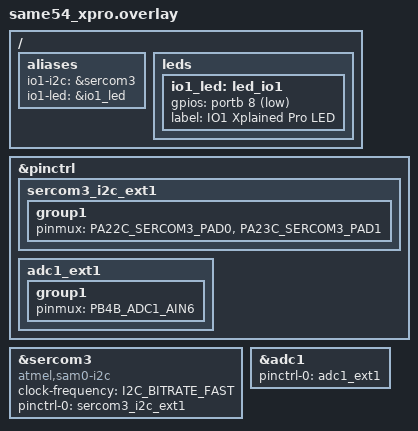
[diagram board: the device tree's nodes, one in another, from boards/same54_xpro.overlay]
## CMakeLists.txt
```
# ml-model-update demo: cloud-updatable ML (IOTM blob) on IO1 Xplained Pro
# sensors. Own src/main.c; uses the quickstart provisioning flow (public CA
# roots only). Regenerate src/model_builtin.h with tools/build_model.py if
# the blob format changes.
cmake_minimum_required(VERSION 3.20.0)
find_package(Zephyr REQUIRED HINTS $ENV{ZEPHYR_BASE})
project(iotc_demo_ml_model_update)

target_sources(app PRIVATE src/main.c)

include(${CMAKE_CURRENT_SOURCE_DIR}/../../common/cmake/iotc_sdk_samples.cmake)

# quickstart_credentials.h: PUBLIC CA roots only (no device key). The
# per-device key/cert is provisioned on-chip (iotcprov provision) into NVS.
target_include_directories(app PRIVATE ${IOTC_SDK_SAMPLES_DIR}/quickstart/src)
```

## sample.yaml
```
sample:
  name: IOTCONNECT ML model update demo
  description: |
    Cloud-updatable tiny-MLP on IO1 Xplained Pro sensors: the model is a
    validated data blob (IOTM) pushed from IOTCONNECT as a C2D command,
    hot-swapped without reflash and persisted to NVS.
common:
  tags: iotconnect ml
  harness: console
tests:
  sample.iotconnect.ml_model_update.build:
    build_only: true
    platform_allow:
      - same54_xpro
```

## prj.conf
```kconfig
# ml-model-update demo - vendor-neutral baseline.
# Board-specific networking/bearer settings live in boards/<board>.conf.

# --- Turn on the SDK (selects the net/TLS/MQTT/SNTP/HTTP stack) -------------
CONFIG_IOTCONNECT=y
CONFIG_IOTCONNECT_DRA=y

# No identity is compiled in: the device is provisioned from the serial
# prompt (quickstart flow) -- iotcprov provision <duid>, register the printed
# cert, paste iotcDeviceConfig.json (iotc config), reboot.
CONFIG_IOTCONNECT_CPID=""
CONFIG_IOTCONNECT_ENV=""
CONFIG_IOTCONNECT_DUID=""
CONFIG_IOTCONNECT_CT_AWS=y
# Region-specific AWS discovery endpoint (from the device config package).
CONFIG_IOTCONNECT_DRA_DISCOVERY_HOST="awsdiscovery.iotconnect.io"

# --- On-device provisioning (identity in NVS + shell commands) --------------
CONFIG_IOTCONNECT_IDENTITY_NVS=y
CONFIG_IOTCONNECT_ONDEVICE_KEYGEN=y
CONFIG_IOTCONNECT_SHELL=y
CONFIG_MBEDTLS_USER_CONFIG_FILE="iotc_mbedtls_config.h"   # enables X509_CREATE_C
CONFIG_PSA_WANT_ALG_ECDSA=y
CONFIG_PSA_WANT_KEY_TYPE_ECC_KEY_PAIR_GENERATE=y
CONFIG_PSA_WANT_KEY_TYPE_ECC_KEY_PAIR_EXPORT=y
CONFIG_PSA_WANT_ECC_SECP_R1_256=y

# --- Shell (base64 cert/key + JSON paste need generous buffers) -------------
CONFIG_SHELL=y
CONFIG_SHELL_CMD_BUFF_SIZE=3072
CONFIG_SHELL_BACKEND_SERIAL_RX_RING_BUFFER_SIZE=4096
CONFIG_SHELL_STACK_SIZE=8192
CONFIG_KERNEL_SHELL=y

# --- Networking (native Zephyr IP stack) -----------------------------------
CONFIG_NETWORKING=y
CONFIG_NET_NATIVE=y
CONFIG_NET_IPV4=y
CONFIG_NET_IPV6=n
CONFIG_NET_TCP=y
CONFIG_NET_UDP=y
CONFIG_NET_SOCKETS=y
CONFIG_NET_SOCKETS_SOCKOPT_TLS=y
CONFIG_NET_SOCKETS_TLS_MAX_CONTEXTS=4
CONFIG_DNS_RESOLVER=y
CONFIG_NET_CONNECTION_MANAGER=y
CONFIG_NET_MGMT=y
CONFIG_NET_MGMT_EVENT=y
CONFIG_POSIX_API=y

# --- TLS / mbedTLS (Zephyr 4.x symbol set) ---------------------------------
CONFIG_TLS_CREDENTIALS=y
CONFIG_MBEDTLS=y
CONFIG_MBEDTLS_ENABLE_HEAP=y
CONFIG_MBEDTLS_HEAP_SIZE=75000
CONFIG_MBEDTLS_SSL_MAX_CONTENT_LEN=16384
CONFIG_MBEDTLS_PEM_PARSE_C=y
CONFIG_MBEDTLS_SSL_SERVER_NAME_INDICATION=y
# Ciphersuites: ECDHE-RSA covers AWS/Azure RSA broker roots; ECDHE-ECDSA covers
# ECC device/broker certs (common with IOTCONNECT). Both AES-128-GCM-SHA256.
CONFIG_MBEDTLS_CIPHERSUITE_TLS_ECDHE_RSA_WITH_AES_128_GCM_SHA256=y
# discovery.iotconnect.io (production instances) only accepts TLS 1.2 CBC suites
CONFIG_MBEDTLS_CIPHERSUITE_TLS_ECDHE_RSA_WITH_AES_128_CBC_SHA256=y
CONFIG_MBEDTLS_CIPHERSUITE_TLS_ECDHE_ECDSA_WITH_AES_128_GCM_SHA256=y
CONFIG_ENTROPY_GENERATOR=y

# --- MQTT / HTTP / SNTP -----------------------------------------------------
CONFIG_MQTT_LIB=y
CONFIG_MQTT_LIB_TLS=y
CONFIG_MQTT_KEEPALIVE=30
CONFIG_HTTP_CLIENT=y
CONFIG_SNTP=y

# --- Time (apply SNTP to realtime clock for cert validity) -----------------
CONFIG_POSIX_TIMERS=y

# --- Settings / NVS (identity + DRA cache persistence) ---------------------
CONFIG_SETTINGS=y
CONFIG_SETTINGS_NVS=y
CONFIG_NVS=y
CONFIG_FLASH=y
CONFIG_FLASH_MAP=y

# --- libc / heap / stacks ---------------------------------------------------
# Board default libc = picolibc. cJSON serializes telemetry doubles via libc
# sprintf("%g"); picolibc needs float printf explicitly enabled or doubles
# render as the literal "*float*".
CONFIG_PICOLIBC_IO_FLOAT=y
CONFIG_MAIN_STACK_SIZE=8192
CONFIG_HEAP_MEM_POOL_SIZE=32768
CONFIG_IOTCONNECT_THREAD_STACK_SIZE=4096

# --- Logging ----------------------------------------------------------------
CONFIG_LOG=y
CONFIG_IOTCONNECT_LOG_LEVEL_INF=y

# ml-model-update: IO1 Xplained Pro sensors + LED, model blob handling.
CONFIG_GPIO=y
CONFIG_I2C=y
CONFIG_ADC=y
# base64 decode of pushed model blobs; CRC32 validation of their weights.
CONFIG_BASE64=y
CONFIG_CRC=y
# C2D "reboot" command.
CONFIG_REBOOT=y

# Device vitals: append a "sys" object (CPU/heap/temp/uptime/reset) to telemetry.
CONFIG_IOTCONNECT_DEVICE_VITALS=y
```

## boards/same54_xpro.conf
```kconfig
# SAM E54 Xplained Pro board config for the ml-model-update demo -- ETHERNET bearer.
#
# The SAME54's GMAC is wired (RMII) to an onboard Microchip KSZ8091 PHY + RJ45,
# and the board devicetree already enables gmac/mdio/phy with the factory MAC
# address read from the onboard AT24MAC402 EEPROM (nvmem cell) -- so no overlay
# is needed. This .conf only turns on L2 + DHCPv4 so the interface
# self-configures and the SDK's connection manager sees L4 up.
#
# NOTE: this targets the legacy Atmel-tree board (`same54_xpro`), which has
# working Ethernet in Zephyr v4.4.1. Microchip's new-tree port of the same
# hardware (`sam_e54_xpro`) has no GMAC node yet; migrate when it lands.

# --- Bearer: native Ethernet (GMAC + KSZ8091 RMII) --------------------------
CONFIG_NET_L2_ETHERNET=y
CONFIG_ETH_SAM_GMAC=y
CONFIG_MDIO=y

# --- IPv4 via DHCP; auto-bring-up the interface ----------------------------
CONFIG_NET_DHCPV4=y
CONFIG_NET_CONFIG_AUTO_INIT=y
CONFIG_NET_CONFIG_NEED_IPV4=y
CONFIG_NET_CONFIG_SETTINGS=y

# --- Net buffers sized for a wired link ------------------------------------
CONFIG_NET_PKT_RX_COUNT=16
CONFIG_NET_PKT_TX_COUNT=16
CONFIG_NET_BUF_RX_COUNT=32
CONFIG_NET_BUF_TX_COUNT=32
CONFIG_NET_CONTEXT_RCVTIMEO=y

# --- mbedTLS heap headroom for cloud broker cert chains --------------------
# 75000 (not the usual 60000): the native AI Model push downloads over a
# SECOND TLS session while the MQTT session stays up, so two handshakes'
# worth of heap must coexist.
CONFIG_MBEDTLS_HEAP_SIZE=75000

# --- Software-crypto speed (no HW accel on SAME54) --------------------------
# Without the NIST-curve optimization, the ECDHE/ECDSA TLS handshake on this
# 120 MHz M4F overruns AWS IoT's ~10 s handshake window and mqtt_connect
# fails with -116 (hardware-observed). ROM AES tables trade flash for setup time.
CONFIG_MBEDTLS_ECP_NIST_OPTIM=y
CONFIG_MBEDTLS_AES_ROM_TABLES=y

# Inbound C2D payloads (model pushes carry a long presigned URL) exceed the
# default 1 KiB log buffer and get dropped -- room to print them whole.
CONFIG_LOG_BUFFER_SIZE=8192

# The model download (iotc_https_download) runs in the C2D worker: its 2 KiB
# HTTP receive buffer lives on the stack and the software-crypto TLS
# handshake needs several KiB more. The 3 KiB default stack overflows
# (hardware-observed MPU fault).
CONFIG_IOTCONNECT_C2D_WORKQ_STACK_SIZE=12288
```

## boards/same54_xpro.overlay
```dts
/*
 * SAM E54 Xplained Pro overlay for the ml-model-update demo -- wires the
 * IO1 Xplained Pro extension on EXT1 (user-guide Atmel-42078):
 *
 *   IO1 EXT pin 3  LIGHTSENSOR (TEMT6000)  -> EXT1 pin 3  = PB04 ADC1/AIN[6]
 *   IO1 EXT pin 7  LED (active low)        -> EXT1 pin 7  = PB08
 *   IO1 EXT pins 11/12  AT30TSE758 I2C     -> EXT1 = SERCOM3 (PA22/PA23)
 *
 * NOTE: EXT1's I2C is SERCOM3 -- its own bus. (EXT2/EXT3 share SERCOM7 with
 * the AT24MAC402 EEPROM and ATECC508; if you move the IO1 there, point
 * io1-i2c at &sercom7 instead.)
 *
 * Ethernet needs no overlay on this board: the devicetree already enables
 * gmac/mdio/phy (KSZ8091 RMII, factory MAC from the AT24MAC402 EEPROM).
 */

#include <zephyr/dt-bindings/i2c/i2c.h>
#include <dt-bindings/pinctrl/same54p-pinctrl.h>

/ {
	aliases {
		io1-i2c = &sercom3;
		io1-led = &io1_led;
	};

	leds {
		io1_led: led_io1 {
			gpios = <&portb 8 GPIO_ACTIVE_LOW>;
			label = "IO1 Xplained Pro LED";
		};
	};
};

&pinctrl {
	sercom3_i2c_ext1: sercom3_i2c_ext1 {
		group1 {
			pinmux = <PA22C_SERCOM3_PAD0>,
				 <PA23C_SERCOM3_PAD1>;
		};
	};

	adc1_ext1: adc1_ext1 {
		group1 {
			pinmux = <PB4B_ADC1_AIN6>;
		};
	};
};

&sercom3 {
	status = "okay";
	compatible = "atmel,sam0-i2c";
	/* 400 kHz, NOT 100 kHz: the i2c_sam0 driver clocks SERCOMs from GCLK0
	 * (120 MHz here) and its 8-bit BAUD divider overflows below ~235 kHz
	 * (-ERANGE at init -> device never ready). AT30TSE758 is fine at 400k. */
	clock-frequency = <I2C_BITRATE_FAST>;
	#address-cells = <1>;
	#size-cells = <0>;

	pinctrl-0 = <&sercom3_i2c_ext1>;
	pinctrl-names = "default";
};

&adc1 {
	status = "okay";

	pinctrl-0 = <&adc1_ext1>;
	pinctrl-names = "default";
};
```

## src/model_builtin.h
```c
/* Generated by tools/build_model.py -- v1 "ambient" model blob.
 * Regenerate with:  python tools/build_model.py  */
#ifndef MODEL_BUILTIN_H
#define MODEL_BUILTIN_H

#include <stdint.h>

static const uint8_t model_builtin[] = {
	0x49, 0x4f, 0x54, 0x4d, 0x01, 0x00, 0x01, 0x00, 0x02, 0x02, 0x03, 0x04,
	0x64, 0x61, 0x72, 0x6b, 0x00, 0x00, 0x00, 0x00, 0x00, 0x00, 0x00, 0x00,
	0x64, 0x69, 0x6d, 0x00, 0x00, 0x00, 0x00, 0x00, 0x00, 0x00, 0x00, 0x00,
	0x62, 0x72, 0x69, 0x67, 0x68, 0x74, 0x00, 0x00, 0x00, 0x00, 0x00, 0x00,
	0x00, 0x00, 0x00, 0x00, 0x00, 0x00, 0x00, 0x00, 0x00, 0x00, 0x00, 0x00,
	0x54, 0xb7, 0xff, 0xc7, 0x00, 0x00, 0x00, 0x00, 0x00, 0x00, 0x80, 0x3f,
	0x00, 0x00, 0x00, 0x00, 0x00, 0x00, 0x80, 0x3f, 0xcd, 0xcc, 0x4c, 0xbe,
	0x9a, 0x99, 0x19, 0xbf, 0x00, 0x00, 0x7a, 0xc4, 0x00, 0x00, 0x00, 0x00,
	0x00, 0x00, 0x7a, 0x44, 0x00, 0x24, 0x74, 0xc9, 0x00, 0x00, 0x00, 0x00,
	0x00, 0x24, 0x74, 0x49, 0x00, 0x00, 0x00, 0x3f, 0x00, 0x00, 0x00, 0x00,
	0x00, 0x00, 0x00, 0xbf,
};

#endif /* MODEL_BUILTIN_H */
```
